# MEC1701Q register map
Vendor: Microchip Technology; Series: MEC1701; File version: 0
CPU: CM4 r1p0, little endian, MPU, FPU, 3 interrupt priority bits
Registers are 32-bit, read-write, reset 0x0 unless marked. A register's access mark holds for its fields unless they carry their own. Offsets are from the block's base; [hi:lo] are bit positions; {n}, {i} and the like mark numbered series.

## TFDP — The TFDP serially transmits Embedded Controller (EC)-originated diagnostic vectors to an external debug trace system.
Base 0x40008C00; register names take the prefix TFDP_
0x00 MSDATA 8-bit — Debug data to be shifted out on the TFDP Debug port. While data is being shifted out, the Host Interface will 'hold-off' additional writes to the data register until the transfer is complete.
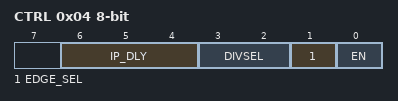
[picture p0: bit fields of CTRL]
0x04 CTRL 8-bit — Debug Control Register
  [6:4] IP_DLY — Inter-packet Delay. The delay is in terms of TFDP Debug output clocks.
  [3:2] DIVSEL — Clock Divider Select.
  [1] EDGE_SEL — 1= Data is shifted out on the falling edge of the debug clock, 0= Data is shifted out on the rising edge of the debug clock (Default)
  [0] EN — Enable. 1=Clock enabled, 0=Clock is disabled (Default)

## VBAT_RAM — The VBAT Powered RAM provides a 128 Byte Random Accessed Memory that is operational while the main power rail is operational, and will retain its values powered by battery power while the main rail is unpowered.
Base 0x4000A800; register names take the prefix VBAT_RAM_
{0x0+4i} MEM_u32[{i}] (i=0..31) — 32-bits of VBAT powered RAM.

## EFUSE — The eFUSE block provides a means of programming and accessing the eFUSE bits.
Base 0x40082000; register names take the prefix EFUSE_
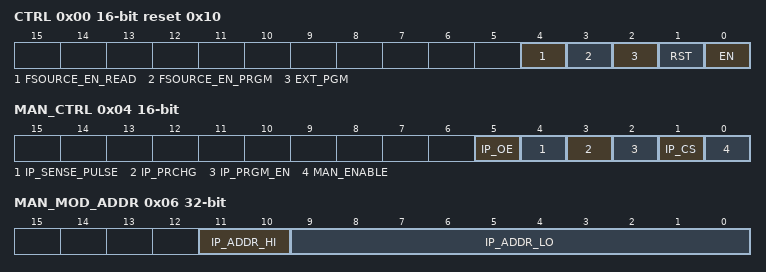
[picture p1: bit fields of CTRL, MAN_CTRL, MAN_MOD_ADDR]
0x00 CTRL 16-bit reset 0x10 — eFUSE CTRL Register
  [4] FSOURCE_EN_READ — FSOURCE pin enable for reading: 1=FSOURCE switch logic connects eFUSE FSOURCE pin to a power pad for read mode. Only set this bit when FSOURCE_EN_PRGM bit is already 0 to avoid shorting the power pad to ground; 0=FSOURCE switch logic isolates eFUSE FSOURCE pin from ground.
  [3] FSOURCE_EN_PRGM — FSOURCE pin enable for programming: 1=FSOURCE switch logic connects eFUSE FSOURCE pin to a power pad for PROGRAM mode. Only set this bit when FSOURCE_EN_READ bit is already 0 to avoid shorting the power pad to ground; 0=FSOURCE switch logic isolates eFUSE FSOURCE pin from power pad.
  [2] EXT_PGM — External programming enable: 1=eFUSE programming is done via external pin interface 0=Manual/Normal mode. eFUSE programming is done via this block's register set.
  [1] RST — Block reset: 1=Block is reset; 0=Normal operation. This bit self-clears and always reads back 0.
  [0] EN — Block enable: 1=block is enabled for operation; 0=block is disabled and in lowest power state.
0x04 MAN_CTRL 16-bit — Manual Control Register
  [5] IP_OE — eFUSE output enable. The IP might tri-state at various times, so this bit isolates the outputs to avoid potential crowbar. 1=eFUSE outputs enabled for read; 0=eFUSE outputs isolated
  [4] IP_SENSE_PULSE — eFUSE sense, outputs are valid on falling edge of this bit.
  [3] IP_PRCHG — eFUSE precharge: 1=outputs are being precharged; 0=outputs are not precharged.
  [2] IP_PRGM_EN — eFUSE program enable. Can also be considered the write signal: 1=eFUSE is programming; 0=eFUSE is in read mode.
  [1] IP_CS — eFUSE chip select (CS) pin: 1=eFUSE is enabled for PROGRAM/READ modes; 0=eFUSE is disabled and in low power state.
  [0] MAN_ENABLE — Manual mode enable bit: 1=Manual mode is enabled and this register interfaces to the eFUSE; 0=Normal mode, internal controller interfaces to eFUSE IP. This bit only takes affect when REG_CTRL.EXT_PRGM bit is 0.
0x06 MAN_MOD_ADDR — MANUAL MODE ADDRESS REGISTER
  [11:10] IP_ADDR_HI — Manual mode address, selecting a 1K bit block of eFuse data
  [9:0] IP_ADDR_LO — Manual mode address, selecting the bit address within a 1K bit block.
0x0C MAN_MOD_DATA — MANUAL MODE DATA REGISTER
  [15:0] IP_DATA — Manual mode data: This field connects to the eFUSE data output pins.
{0x10+4i} EFUSE_MEM_DW[{i}] (i=0..127) — 512 Bytes of EFUSE Memory (IP_MEM) Represented in 128 DW chunks: eFUSE memory read-back data. Access to this region depends on the operating mode: NORMAL MODE: Reading any of the bytes starting at this base will automatically start the controller to sequence all eFUSE signals to generate read data. Wait cycles added to the read cycle as appropriate. MANUAL MODE: Refer to the manual mode section for the proper procedure for accessing data in this mode. See REG_MAN_CTRL.MAN_EN and REG_CTRL.EXT_PRGM bits for controlling the operating mode of the block.
